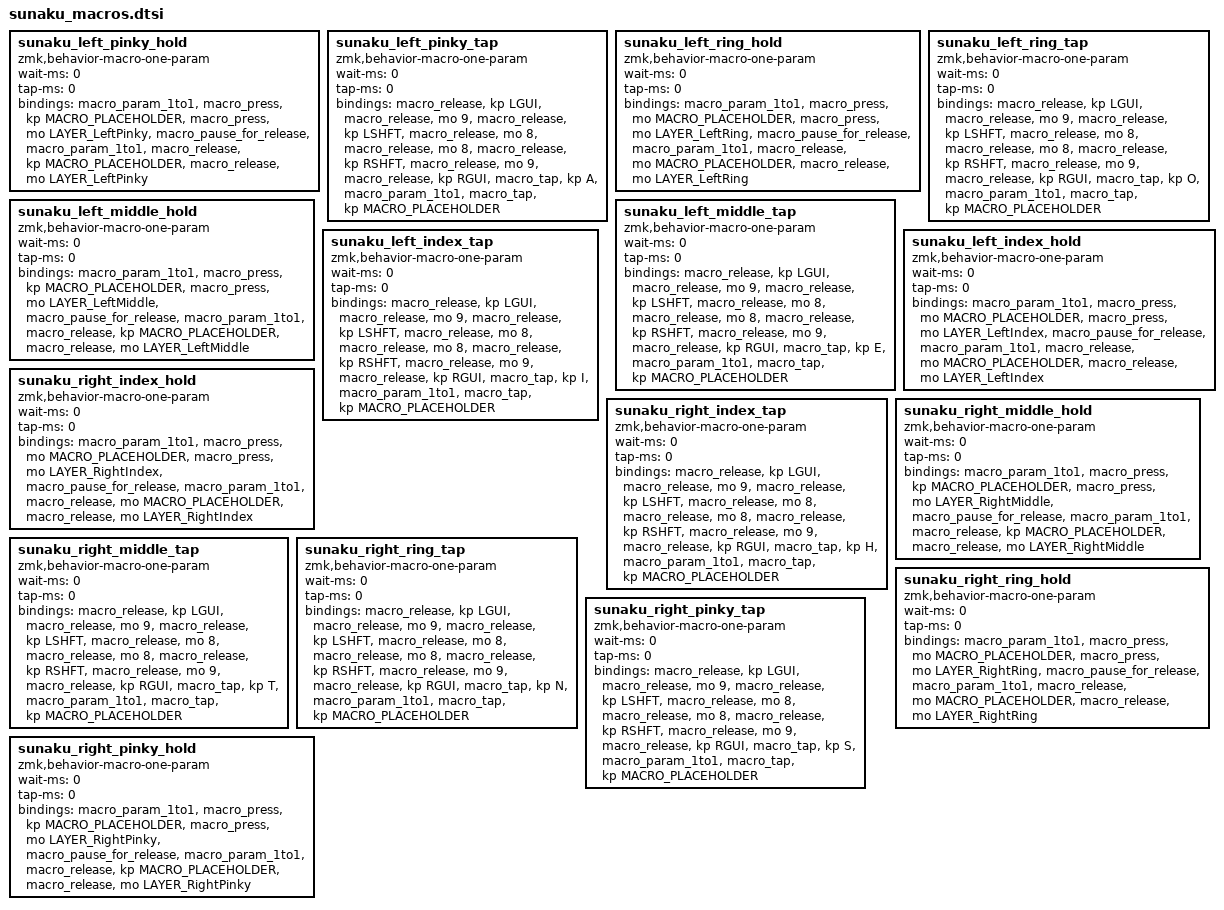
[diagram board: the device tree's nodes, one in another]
// Generated by generate_sunaku.py
        sunaku_left_pinky_hold: sunaku_left_pinky_hold {
            compatible = "zmk,behavior-macro-one-param";
            wait-ms = <0>;
            tap-ms = <0>;
            #binding-cells = <1>;
            bindings = <&macro_param_1to1>
                     , <&macro_press &kp MACRO_PLACEHOLDER>
                     , <&macro_press &mo LAYER_LeftPinky>
                     , <&macro_pause_for_release>
                     , <&macro_param_1to1>
                     , <&macro_release &kp MACRO_PLACEHOLDER>
                     , <&macro_release &mo LAYER_LeftPinky>;
        };

        sunaku_left_pinky_tap: sunaku_left_pinky_tap {
            compatible = "zmk,behavior-macro-one-param";
            wait-ms = <0>;
            tap-ms = <0>;
            #binding-cells = <1>;
            bindings = <&macro_release &kp LGUI>
                     , <&macro_release &mo 9>
                     , <&macro_release &kp LSHFT>
                     , <&macro_release &mo 8>
                     , <&macro_release &mo 8>
                     , <&macro_release &kp RSHFT>
                     , <&macro_release &mo 9>
                     , <&macro_release &kp RGUI>
                     , <&macro_tap &kp A>
                     , <&macro_param_1to1>
                     , <&macro_tap &kp MACRO_PLACEHOLDER>;
        };

        sunaku_left_ring_hold: sunaku_left_ring_hold {
            compatible = "zmk,behavior-macro-one-param";
            wait-ms = <0>;
            tap-ms = <0>;
            #binding-cells = <1>;
            bindings = <&macro_param_1to1>
                     , <&macro_press &mo MACRO_PLACEHOLDER>
                     , <&macro_press &mo LAYER_LeftRing>
                     , <&macro_pause_for_release>
                     , <&macro_param_1to1>
                     , <&macro_release &mo MACRO_PLACEHOLDER>
                     , <&macro_release &mo LAYER_LeftRing>;
        };

        sunaku_left_ring_tap: sunaku_left_ring_tap {
            compatible = "zmk,behavior-macro-one-param";
            wait-ms = <0>;
            tap-ms = <0>;
            #binding-cells = <1>;
            bindings = <&macro_release &kp LGUI>
                     , <&macro_release &mo 9>
                     , <&macro_release &kp LSHFT>
                     , <&macro_release &mo 8>
                     , <&macro_release &mo 8>
                     , <&macro_release &kp RSHFT>
                     , <&macro_release &mo 9>
                     , <&macro_release &kp RGUI>
                     , <&macro_tap &kp O>
                     , <&macro_param_1to1>
                     , <&macro_tap &kp MACRO_PLACEHOLDER>;
        };

        sunaku_left_middle_hold: sunaku_left_middle_hold {
            compatible = "zmk,behavior-macro-one-param";
            wait-ms = <0>;
            tap-ms = <0>;
            #binding-cells = <1>;
            bindings = <&macro_param_1to1>
                     , <&macro_press &kp MACRO_PLACEHOLDER>
                     , <&macro_press &mo LAYER_LeftMiddle>
                     , <&macro_pause_for_release>
                     , <&macro_param_1to1>
                     , <&macro_release &kp MACRO_PLACEHOLDER>
                     , <&macro_release &mo LAYER_LeftMiddle>;
        };

        sunaku_left_middle_tap: sunaku_left_middle_tap {
            compatible = "zmk,behavior-macro-one-param";
            wait-ms = <0>;
            tap-ms = <0>;
            #binding-cells = <1>;
            bindings = <&macro_release &kp LGUI>
                     , <&macro_release &mo 9>
                     , <&macro_release &kp LSHFT>
                     , <&macro_release &mo 8>
                     , <&macro_release &mo 8>
                     , <&macro_release &kp RSHFT>
                     , <&macro_release &mo 9>
                     , <&macro_release &kp RGUI>
                     , <&macro_tap &kp E>
                     , <&macro_param_1to1>
                     , <&macro_tap &kp MACRO_PLACEHOLDER>;
        };

        sunaku_left_index_hold: sunaku_left_index_hold {
            compatible = "zmk,behavior-macro-one-param";
            wait-ms = <0>;
            tap-ms = <0>;
            #binding-cells = <1>;
            bindings = <&macro_param_1to1>
                     , <&macro_press &mo MACRO_PLACEHOLDER>
                     , <&macro_press &mo LAYER_LeftIndex>
                     , <&macro_pause_for_release>
                     , <&macro_param_1to1>
                     , <&macro_release &mo MACRO_PLACEHOLDER>
                     , <&macro_release &mo LAYER_LeftIndex>;
        };

        sunaku_left_index_tap: sunaku_left_index_tap {
            compatible = "zmk,behavior-macro-one-param";
            wait-ms = <0>;
            tap-ms = <0>;
            #binding-cells = <1>;
            bindings = <&macro_release &kp LGUI>
                     , <&macro_release &mo 9>
                     , <&macro_release &kp LSHFT>
                     , <&macro_release &mo 8>
                     , <&macro_release &mo 8>
                     , <&macro_release &kp RSHFT>
                     , <&macro_release &mo 9>
                     , <&macro_release &kp RGUI>
                     , <&macro_tap &kp I>
                     , <&macro_param_1to1>
                     , <&macro_tap &kp MACRO_PLACEHOLDER>;
        };

        sunaku_right_index_hold: sunaku_right_index_hold {
            compatible = "zmk,behavior-macro-one-param";
            wait-ms = <0>;
            tap-ms = <0>;
            #binding-cells = <1>;
            bindings = <&macro_param_1to1>
                     , <&macro_press &mo MACRO_PLACEHOLDER>
                     , <&macro_press &mo LAYER_RightIndex>
                     , <&macro_pause_for_release>
                     , <&macro_param_1to1>
                     , <&macro_release &mo MACRO_PLACEHOLDER>
                     , <&macro_release &mo LAYER_RightIndex>;
        };

        sunaku_right_index_tap: sunaku_right_index_tap {
            compatible = "zmk,behavior-macro-one-param";
            wait-ms = <0>;
            tap-ms = <0>;
            #binding-cells = <1>;
            bindings = <&macro_release &kp LGUI>
                     , <&macro_release &mo 9>
                     , <&macro_release &kp LSHFT>
                     , <&macro_release &mo 8>
                     , <&macro_release &mo 8>
                     , <&macro_release &kp RSHFT>
                     , <&macro_release &mo 9>
                     , <&macro_release &kp RGUI>
                     , <&macro_tap &kp H>
                     , <&macro_param_1to1>
                     , <&macro_tap &kp MACRO_PLACEHOLDER>;
        };

        sunaku_right_middle_hold: sunaku_right_middle_hold {
            compatible = "zmk,behavior-macro-one-param";
            wait-ms = <0>;
            tap-ms = <0>;
            #binding-cells = <1>;
            bindings = <&macro_param_1to1>
                     , <&macro_press &kp MACRO_PLACEHOLDER>
                     , <&macro_press &mo LAYER_RightMiddle>
                     , <&macro_pause_for_release>
                     , <&macro_param_1to1>
                     , <&macro_release &kp MACRO_PLACEHOLDER>
                     , <&macro_release &mo LAYER_RightMiddle>;
        };

        sunaku_right_middle_tap: sunaku_right_middle_tap {
            compatible = "zmk,behavior-macro-one-param";
            wait-ms = <0>;
            tap-ms = <0>;
            #binding-cells = <1>;
            bindings = <&macro_release &kp LGUI>
                     , <&macro_release &mo 9>
                     , <&macro_release &kp LSHFT>
                     , <&macro_release &mo 8>
                     , <&macro_release &mo 8>
                     , <&macro_release &kp RSHFT>
                     , <&macro_release &mo 9>
                     , <&macro_release &kp RGUI>
                     , <&macro_tap &kp T>
                     , <&macro_param_1to1>
                     , <&macro_tap &kp MACRO_PLACEHOLDER>;
        };

        sunaku_right_ring_hold: sunaku_right_ring_hold {
            compatible = "zmk,behavior-macro-one-param";
            wait-ms = <0>;
            tap-ms = <0>;
            #binding-cells = <1>;
            bindings = <&macro_param_1to1>
                     , <&macro_press &mo MACRO_PLACEHOLDER>
                     , <&macro_press &mo LAYER_RightRing>
                     , <&macro_pause_for_release>
                     , <&macro_param_1to1>
                     , <&macro_release &mo MACRO_PLACEHOLDER>
                     , <&macro_release &mo LAYER_RightRing>;
        };

        sunaku_right_ring_tap: sunaku_right_ring_tap {
            compatible = "zmk,behavior-macro-one-param";
            wait-ms = <0>;
            tap-ms = <0>;
            #binding-cells = <1>;
            bindings = <&macro_release &kp LGUI>
                     , <&macro_release &mo 9>
                     , <&macro_release &kp LSHFT>
                     , <&macro_release &mo 8>
                     , <&macro_release &mo 8>
                     , <&macro_release &kp RSHFT>
                     , <&macro_release &mo 9>
                     , <&macro_release &kp RGUI>
                     , <&macro_tap &kp N>
                     , <&macro_param_1to1>
                     , <&macro_tap &kp MACRO_PLACEHOLDER>;
        };

        sunaku_right_pinky_hold: sunaku_right_pinky_hold {
            compatible = "zmk,behavior-macro-one-param";
            wait-ms = <0>;
            tap-ms = <0>;
            #binding-cells = <1>;
            bindings = <&macro_param_1to1>
                     , <&macro_press &kp MACRO_PLACEHOLDER>
                     , <&macro_press &mo LAYER_RightPinky>
                     , <&macro_pause_for_release>
                     , <&macro_param_1to1>
                     , <&macro_release &kp MACRO_PLACEHOLDER>
                     , <&macro_release &mo LAYER_RightPinky>;
        };

        sunaku_right_pinky_tap: sunaku_right_pinky_tap {
            compatible = "zmk,behavior-macro-one-param";
            wait-ms = <0>;
            tap-ms = <0>;
            #binding-cells = <1>;
            bindings = <&macro_release &kp LGUI>
                     , <&macro_release &mo 9>
                     , <&macro_release &kp LSHFT>
                     , <&macro_release &mo 8>
                     , <&macro_release &mo 8>
                     , <&macro_release &kp RSHFT>
                     , <&macro_release &mo 9>
                     , <&macro_release &kp RGUI>
                     , <&macro_tap &kp S>
                     , <&macro_param_1to1>
                     , <&macro_tap &kp MACRO_PLACEHOLDER>;
        };

